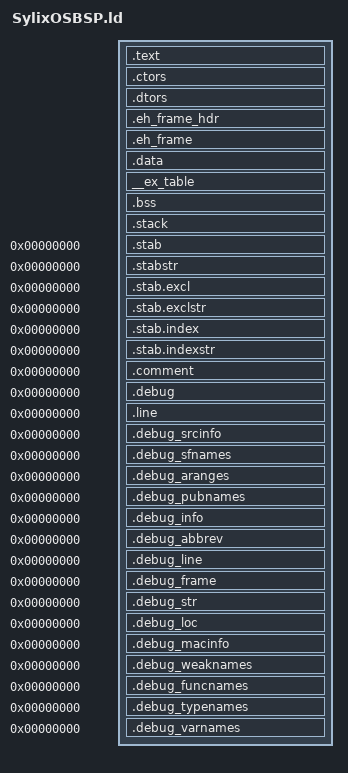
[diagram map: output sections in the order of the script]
/****************************************Copyright (c)****************************************************
**                            Beijin ACOINFO electronics Co.,LTD.
**
**                                 http://www.sylixos.com
**
**--------------File Info---------------------------------------------------------------------------------
** File name:               SylixOSBSP.ld
** Last modified Date:      2009-01-04
** Last Version:            0.01
** Descriptions:            bspmips Linker Script File
**
**--------------------------------------------------------------------------------------------------------
** Created by:              Han.hui
** Created date:            2009-01-04
** Version:                 0.01
** Descriptions:            创建版本
**
**--------------------------------------------------------------------------------------------------------
** Modified by:
** Modified date:
** Version:
** Descriptions:
**
*********************************************************************************************************/
INCLUDE "config.ld"

/*********************************************************************************************************
    链接配置
*********************************************************************************************************/

STACK_SIZE = 0x10000;                                                   /*  stack size config           */
OUTPUT_FORMAT("elf32-tradlittlemips")                                   /*  binary file format          */
OUTPUT_ARCH(mips)                                                       /*  target select               */

/*********************************************************************************************************
    段定义
*********************************************************************************************************/

SECTIONS
{
   
/*********************************************************************************************************
    代码段  LMA == VMA == RAM 起始位置
*********************************************************************************************************/

    .text : {
        *(.vector)
        *(.text)
        *(.text.*)                                                      /*  cpp namespace function      */
        *(.romrun)                                                      /*  ROM 中必须的函数            */
        *(.rodata)                                                      /*  read-only data (constants)  */
        *(.rodata*)
        *(.glue_7)
        *(.glue_7t)
        *(.rel.dyn)
    } > RAM

/*********************************************************************************************************
    C++ 全局对象构造与析构函数表 

    这里放在 .text 之后, .data 之前, 
    这里的  LMA 和 VMA 相同, 如果放在 .data 之后, LMA 与 VMA 不同, 则需要启动程序从装载区搬运到运行区
*********************************************************************************************************/

    . = ALIGN(4);
    .ctors : {
        KEEP (*cppRtBegin*.o(.ctors))
        KEEP (*(.preinit_array))
        KEEP (*(.init_array))
        KEEP (*(SORT(.ctors.*)))
        KEEP (*(.ctors))
        KEEP (*cppRtEnd*.o(.ctors))
    } > RAM
  
    .dtors : {
        KEEP (*cppRtBegin*.o(.dtors))
        KEEP (*(.fini_array))
        KEEP (*(SORT(.dtors.*)))
        KEEP (*(.dtors))
        KEEP (*cppRtEnd*.o(.dtors))
    } > RAM

/*********************************************************************************************************
    .Build OK
*********************************************************************************************************/
    
    .eh_frame_hdr : ALIGN (4) {
        KEEP (*(.eh_frame_hdr))
        *(.eh_frame_entry .eh_frame_entry.*)
    } > RAM
    
    .eh_frame : ALIGN (4) {
        KEEP (*(.eh_frame)) *(.eh_frame.*)
    } > RAM

/*********************************************************************************************************
    .data 段数据初始化内容放在这里
*********************************************************************************************************/

    _etext = . ;
    PROVIDE (etext = .);

/*********************************************************************************************************
     数据段

     .data 段运行地址 VMA 为 SYLIXOS_DATA_START 装载地址 LMA 为  _etext.
     连接器会将 .data 的初始化数据放在  _etext 的地方, 然后启动程序必须将 _etext 的内容搬运到 
     VMA SYLIXOS_DATA_START 中. 大小等于 SIZEOF(.data)
*********************************************************************************************************/

    .data SYLIXOS_DATA_START : AT (_etext) {
        . = ALIGN(4);
         _data = . ;
         *(.data)
         
        . = ALIGN(4);
        _gp = . + 0x7ff0;
        *(.sdata)
        *(.sbss)
        *(.scommon)
    } > RAM
    
    __ex_table : { 
        *(__ex_table) 
    } > RAM
    
    _edata = ADDR(.data) + SIZEOF(.data);
    PROVIDE (edata = _edata);

/*********************************************************************************************************
    清零段

    NOLOAD 表示不装载, 启动程序只需要借助 __bss_start 和 __bss_end 两个符号指定的起始地址和结束地址
    将 .bss 区域清零即可. (注意 *.noinit 可以不进行清零)
*********************************************************************************************************/

    .bss (NOLOAD) : {
        . = ALIGN(4);
        *(.noinit)
        PROVIDE (__bss_start = .);
        *(.bss)
        *(COMMON)
        . = ALIGN(4);
        . = ALIGN(4);
        PROVIDE (__bss_end = .);
    } > RAM

/*********************************************************************************************************
    堆栈段段 (SylixOS 运行时不使用)
*********************************************************************************************************/

    .stack : {
        . += STACK_SIZE;
        PROVIDE (_stack = .);
    } > RAM

/*********************************************************************************************************
    Stabs debugging sections
*********************************************************************************************************/

    .stab               0 : {*(.stab) }
    .stabstr            0 : {*(.stabstr) }
    .stab.excl          0 : {*(.stab.excl) }
    .stab.exclstr       0 : {*(.stab.exclstr) }
    .stab.index         0 : {*(.stab.index) }
    .stab.indexstr      0 : {*(.stab.indexstr) }
    .comment            0 : {*(.comment) }

/*********************************************************************************************************
    Symbols in the DWARF debugging sections are relative to the beginning
    of the section so we begin them at 0.
*********************************************************************************************************/

/*********************************************************************************************************
    DWARF 1
*********************************************************************************************************/

    .debug              0 : {*(.debug) }
    .line               0 : {*(.line) }

/*********************************************************************************************************
    GNU DWARF 1 extensions
*********************************************************************************************************/

    .debug_srcinfo      0 : {*(.debug_srcinfo) }
    .debug_sfnames      0 : {*(.debug_sfnames) }

/*********************************************************************************************************
    DWARF 1.1 and DWARF 2
*********************************************************************************************************/

    .debug_aranges      0 : {*(.debug_aranges) }
    .debug_pubnames     0 : {*(.debug_pubnames) }

/*********************************************************************************************************
    DWARF 2
*********************************************************************************************************/

    .debug_info         0 : {*(.debug_info .gnu.linkonce.wi.*) }
    .debug_abbrev       0 : {*(.debug_abbrev) }
    .debug_line         0 : {*(.debug_line) }
    .debug_frame        0 : {*(.debug_frame) }
    .debug_str          0 : {*(.debug_str) }
    .debug_loc          0 : {*(.debug_loc) }
    .debug_macinfo      0 : {*(.debug_macinfo) }

/*********************************************************************************************************
    SGI/MIPS DWARF 2 extensions
*********************************************************************************************************/

    .debug_weaknames    0 : {*(.debug_weaknames) }
    .debug_funcnames    0 : {*(.debug_funcnames) }
    .debug_typenames    0 : {*(.debug_typenames) }
    .debug_varnames     0 : {*(.debug_varnames) }
}

/*********************************************************************************************************
  END FILE
*********************************************************************************************************/
